/*---------GLOBAL DEFINITIONS-----------*/
LIN_description_file;
LIN_protocol_version = "2.1";
LIN_language_version = "2.1";
LIN_speed = 19.2 kbps;
/* ----------NODE DEFINITIONS---------- */
Nodes {
   Master:
      TM3Ecu, /* Master node name */
      5.0 ms, /* Time base */
      0.5 ms; /* Jitter */
   Slaves:
      TM3Sensor;
}
/* ----------SIGNAL DEFINITIONS---------- */
Signals {
   /* Signal_name : Size, Init, Publisher, Subscriber(s) */
   SensorError : 1, 0x0, TM3Sensor, TM3Ecu;
   SensorErrorCode : 8, 0x0, TM3Sensor, TM3Ecu;
   SensorErrorValue : 8, 0x0, TM3Sensor, TM3Ecu;
   Humidity : 16, {0x0,0x0}, TM3Sensor, TM3Ecu;
   LuminosityA : 16, {0x0,0x0}, TM3Sensor, TM3Ecu;
   LuminosityB : 16, {0x0,0x0}, TM3Sensor, TM3Ecu;
   Temperature : 16, {0x0,0x0}, TM3Sensor, TM3Ecu;
   LuminosityA2 : 16, {0x0,0x0}, TM3Sensor, TM3Ecu;
   LuminosityB2 : 16, {0x0,0x0}, TM3Sensor, TM3Ecu;
}
/* ----------DIAGNOSTIC SIGNAL DEFINITIONS---------- */
Diagnostic_signals {
   /* MasterReq Reserved Signals */
   MasterReqB0 : 8, 0;
   MasterReqB1 : 8, 0;
   MasterReqB2 : 8, 0;
   MasterReqB3 : 8, 0;
   MasterReqB4 : 8, 0;
   MasterReqB5 : 8, 0;
   MasterReqB6 : 8, 0;
   MasterReqB7 : 8, 0;
   /* SlaveResp Reserved Signals */
   SlaveRespB0 : 8, 0;
   SlaveRespB1 : 8, 0;
   SlaveRespB2 : 8, 0;
   SlaveRespB3 : 8, 0;
   SlaveRespB4 : 8, 0;
   SlaveRespB5 : 8, 0;
   SlaveRespB6 : 8, 0;
   SlaveRespB7 : 8, 0;
}
/* ----------UNCONDITIONAL FRAME DEFINITIONS---------- */
Frames {
   Humidity_f : 0x5, TM3Sensor , 2 {
      Humidity , 0;
   }
   LuminosityA_f : 0xa, TM3Sensor , 2 {
      LuminosityA , 0;
   }
   LuminosityB_f : 0x12, TM3Sensor , 2 {
      LuminosityB , 0;
   }
   Temperature_f : 0x14, TM3Sensor , 2 {
      Temperature , 0;
   }
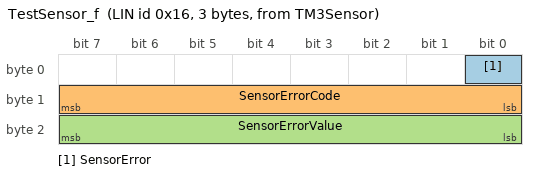
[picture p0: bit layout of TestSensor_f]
   TestSensor_f : 0x16, TM3Sensor , 3 {
      SensorError , 0;
      SensorErrorCode , 8;
      SensorErrorValue , 16;
   }
   LuminosityA2_f : 0xb, TM3Sensor , 2 {
      LuminosityA2 , 0;
   }
   LuminosityB2_f : 0x13, TM3Sensor , 2 {
      LuminosityB2 , 0;
   }
}
/* ----------DIAGNOSTIC FRAME DEFINITIONS---------- */
Diagnostic_frames {
   MasterReq : 0x3c {
      MasterReqB0 , 0;
      MasterReqB1 , 8;
      MasterReqB2 , 16;
      MasterReqB3 , 24;
      MasterReqB4 , 32;
      MasterReqB5 , 40;
      MasterReqB6 , 48;
      MasterReqB7 , 56;
   }
   SlaveResp : 0x3d {
      SlaveRespB0 , 0;
      SlaveRespB1 , 8;
      SlaveRespB2 , 16;
      SlaveRespB3 , 24;
      SlaveRespB4 , 32;
      SlaveRespB5 , 40;
      SlaveRespB6 , 48;
      SlaveRespB7 , 56;
   }
}
/* ----------NODE ATTRIBUTE DEFINITIONS---------- */
Node_attributes {
   TM3Sensor {
      LIN_protocol = "2.1"; /* Node protocol version */
      configured_NAD = 0x5; /* configured NAD of node (1-125) */
      initial_NAD = 0x5; /* initial NAD of node (1-125) */
      product_id = 0x1e, 0x2, 0x1; /* Product id */
      response_error = SensorError; /* Response error signal */
      P2_min = 50 ms; /* P2_min */
      ST_min = 0 ms; /* ST_min */
      N_As_timeout = 1000 ms; /* N_As timeout value */
      N_Cr_timeout = 1000 ms; /* N_Cr timeout value */
      configurable_frames {
         Humidity_f;
         LuminosityA_f;
         LuminosityB_f;
         Temperature_f;
         TestSensor_f;
         LuminosityA2_f;
         LuminosityB2_f;
      }
   }
}
/* ----------SCHEDULE TABLE DEFINITIONS---------- */
Schedule_tables {
   NormalTable {
      Humidity_f delay 15.0 ms;
      LuminosityA_f delay 15.0 ms;
      LuminosityB_f delay 15.0 ms;
      Temperature_f delay 15.0 ms;
      TestSensor_f delay 15.0 ms;
      TestSensor_f delay 15.0 ms;
      LuminosityA2_f delay 15.0 ms;
      LuminosityB2_f delay 15.0 ms;
   }
   InitTable {
      AssignNAD {TM3Sensor} delay 50.0 ms;
      SlaveResp delay 50.0 ms;
      AssignFrameIdRange {TM3Sensor, 0} delay 50.0 ms;
      AssignFrameIdRange {TM3Sensor, 4} delay 50.0 ms;
   }
   DiagnosticTable {
      MasterReq delay 15.0 ms;
      SlaveResp delay 15.0 ms;
   }
}
